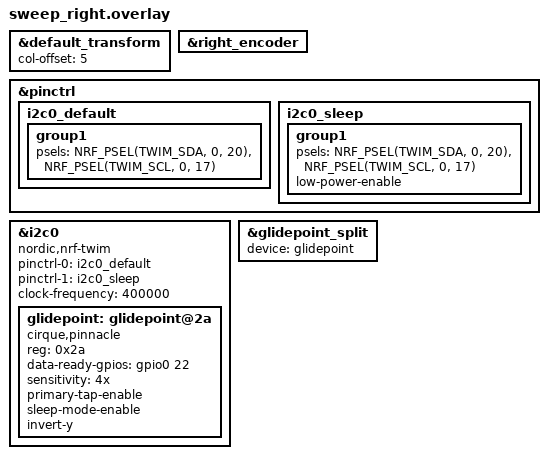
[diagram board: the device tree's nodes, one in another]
#include "sweep.dtsi"

&default_transform {
	col-offset = <5>;
};

&right_encoder {
	status = "okay";
};

&pinctrl {
	/* configuration for i2c0 device, default state */
	i2c0_default: i2c0_default {
		group1 {
			psels = <NRF_PSEL(TWIM_SDA, 0, 20)>,
			<NRF_PSEL(TWIM_SCL, 0, 17)>;
		};
	};
	
	i2c0_sleep: i2c0_sleep {
		group1 {
			psels = <NRF_PSEL(TWIM_SDA, 0, 20)>,
			<NRF_PSEL(TWIM_SCL, 0, 17)>;
			low-power-enable;
		};
	};
};

&i2c0 {
	compatible = "nordic,nrf-twim";// I2C controller instead of generic
	status = "okay";
	
	pinctrl-0 = <&i2c0_default>;
	pinctrl-1 = <&i2c0_sleep>;
	pinctrl-names = "default", "sleep";
	
	clock-frequency = <400000>;
	
	glidepoint: glidepoint@2a{
		compatible = "cirque,pinnacle";
		reg = <0x2a>;
		status = "okay";
		
		data-ready-gpios = <&gpio0 22 (GPIO_ACTIVE_HIGH)>;
		sensitivity = "4x";
		primary-tap-enable;
		sleep-mode-enable;
		invert-y;
	};
};

&glidepoint_split {
	device = <&glidepoint>;
};
